# STM32F070RBT6 register map
File version: 1.0
Registers are 32-bit, access not given, reset 0x0 unless marked. A register's access mark holds for its fields unless they carry their own. Offsets are from the block's base; [hi:lo] are bit positions; {n}, {i} and the like mark numbered series.

## WWDG
Base 0x40002C00
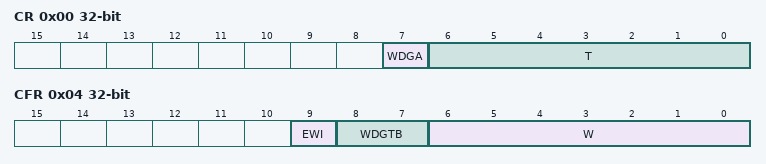
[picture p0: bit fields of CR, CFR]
0x00 CR
  [7] WDGA, [6:0] T
0x04 CFR
  [9] EWI, [8:7] WDGTB, [6:0] W
0x08 SR
  [0] EWIF

## IWDG
Base 0x40003000
0x00 KR
  [15:0] KEY
0x04 PR
  [2:0] PR
0x08 RLR
  [11:0] RL
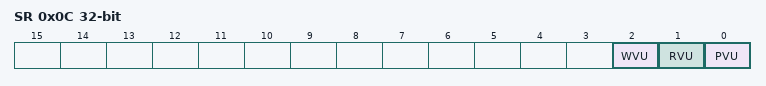
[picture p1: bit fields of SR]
0x0C SR
  [2] WVU, [1] RVU, [0] PVU
0x10 WINR
  [11:0] WIN

## SPI2
Base 0x40003800
Same registers: SPI1 0x40013000
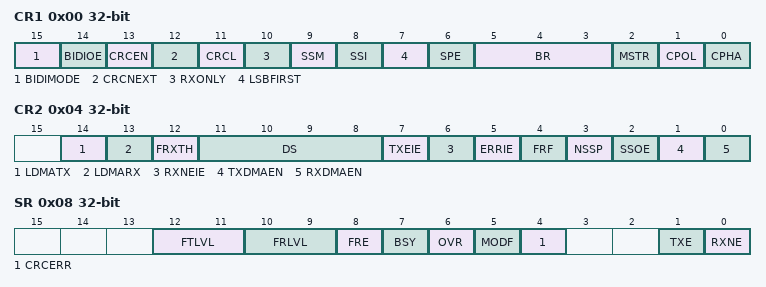
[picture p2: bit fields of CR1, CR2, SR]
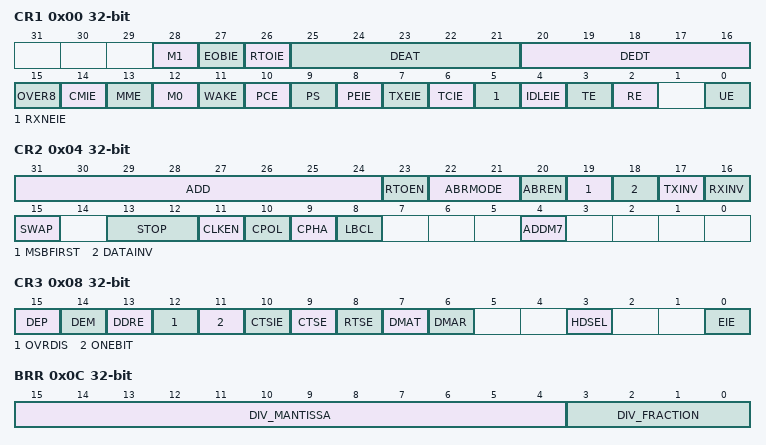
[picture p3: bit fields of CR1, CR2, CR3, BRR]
0x00 CR1
  [15] BIDIMODE, [14] BIDIOE, [13] CRCEN, [12] CRCNEXT, [11] CRCL, [10] RXONLY, [9] SSM, [8] SSI, [7] LSBFIRST, [6] SPE, [5:3] BR, [2] MSTR, [1] CPOL, [0] CPHA
0x04 CR2
  [14] LDMATX, [13] LDMARX, [12] FRXTH, [11:8] DS, [7] TXEIE, [6] RXNEIE, [5] ERRIE, [4] FRF, [3] NSSP, [2] SSOE, [1] TXDMAEN, [0] RXDMAEN
0x08 SR
  [12:11] FTLVL, [10:9] FRLVL, [8] FRE, [7] BSY, [6] OVR, [5] MODF, [4] CRCERR, [1] TXE, [0] RXNE
0x0C DR
0x10 CRCPR
  [31:0] CRCPOLY
0x14 RXCRCR
  [31:0] RXCRC
0x18 TXCRCR
  [31:0] TXCRC
0x1C I2SCFGR
  [11] I2SMOD

## USART2
Base 0x40004400
Same registers: USART3 0x40004800, USART4 0x40004C00, USART1 0x40013800
0x00 CR1
  [28] M1, [27] EOBIE, [26] RTOIE, [25:21] DEAT, [20:16] DEDT, [15] OVER8, [14] CMIE, [13] MME, [12] M0, [11] WAKE, [10] PCE, [9] PS, [8] PEIE, [7] TXEIE, [6] TCIE, [5] RXNEIE, [4] IDLEIE, [3] TE, [2] RE, [0] UE
0x04 CR2
  [31:24] ADD, [23] RTOEN, [22:21] ABRMODE, [20] ABREN, [19] MSBFIRST, [18] DATAINV, [17] TXINV, [16] RXINV, [15] SWAP, [13:12] STOP, [11] CLKEN, [10] CPOL, [9] CPHA, [8] LBCL, [4] ADDM7
0x08 CR3
  [15] DEP, [14] DEM, [13] DDRE, [12] OVRDIS, [11] ONEBIT, [10] CTSIE, [9] CTSE, [8] RTSE, [7] DMAT, [6] DMAR, [3] HDSEL, [0] EIE
0x0C BRR
  [15:4] DIV_MANTISSA, [3:0] DIV_FRACTION
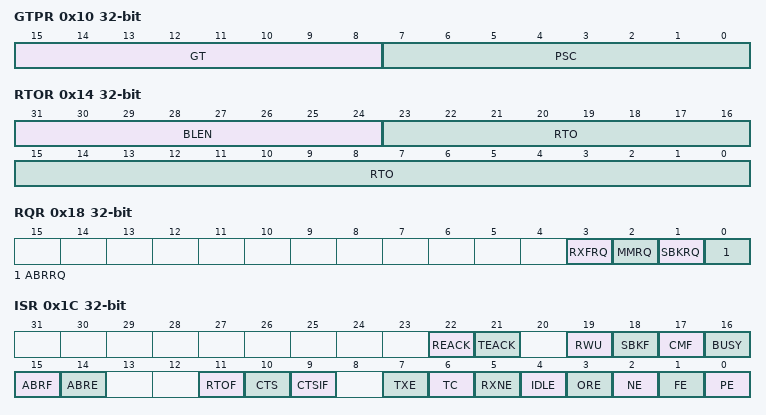
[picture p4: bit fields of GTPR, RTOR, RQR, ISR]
0x10 GTPR
  [15:8] GT, [7:0] PSC
0x14 RTOR
  [31:24] BLEN, [23:0] RTO
0x18 RQR
  [3] RXFRQ, [2] MMRQ, [1] SBKRQ, [0] ABRRQ
0x1C ISR
  [22] REACK, [21] TEACK, [19] RWU, [18] SBKF, [17] CMF, [16] BUSY, [15] ABRF, [14] ABRE, [11] RTOF, [10] CTS, [9] CTSIF, [7] TXE, [6] TC, [5] RXNE, [4] IDLE, [3] ORE, [2] NE, [1] FE, [0] PE
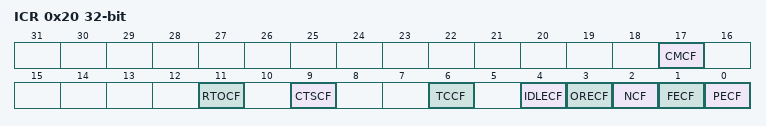
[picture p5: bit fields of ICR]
0x20 ICR
  [17] CMCF, [11] RTOCF, [9] CTSCF, [6] TCCF, [4] IDLECF, [3] ORECF, [2] NCF, [1] FECF, [0] PECF
0x24 RDR 16-bit
0x28 TDR 16-bit

## I2C1
Base 0x40005400
Same registers: I2C2 0x40005800
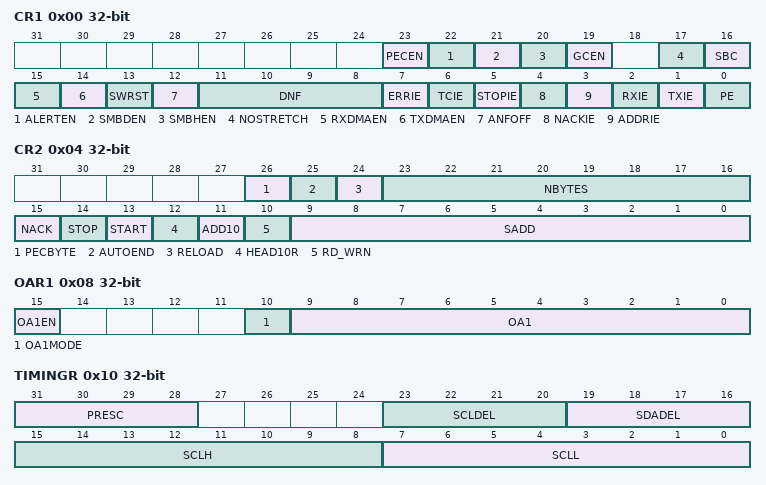
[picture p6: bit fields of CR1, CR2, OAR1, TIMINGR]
0x00 CR1
  [23] PECEN, [22] ALERTEN, [21] SMBDEN, [20] SMBHEN, [19] GCEN, [17] NOSTRETCH, [16] SBC, [15] RXDMAEN, [14] TXDMAEN, [13] SWRST, [12] ANFOFF, [11:8] DNF, [7] ERRIE, [6] TCIE, [5] STOPIE, [4] NACKIE, [3] ADDRIE, [2] RXIE, [1] TXIE, [0] PE
0x04 CR2
  [26] PECBYTE, [25] AUTOEND, [24] RELOAD, [23:16] NBYTES, [15] NACK, [14] STOP, [13] START, [12] HEAD10R, [11] ADD10, [10] RD_WRN, [9:0] SADD
0x08 OAR1
  [15] OA1EN, [10] OA1MODE, [9:0] OA1
0x0C OAR2
  [15] OA2EN, [10] OA2MASK04, [10:9] OA2MASK06, [10:8] OA2MSK, [7:1] OA2
0x10 TIMINGR
  [31:28] PRESC, [23:20] SCLDEL, [19:16] SDADEL, [15:8] SCLH, [7:0] SCLL
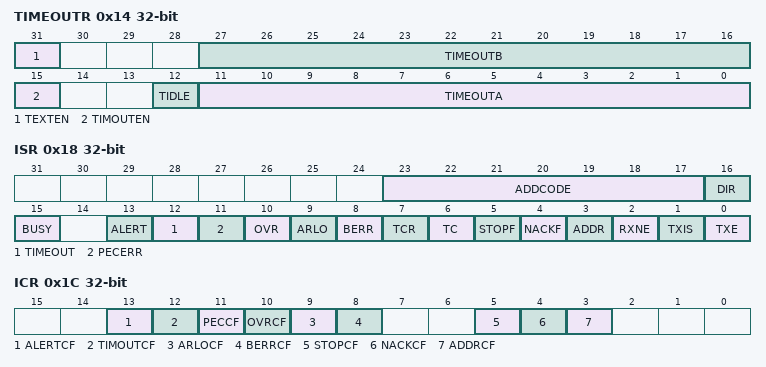
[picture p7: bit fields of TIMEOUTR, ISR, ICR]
0x14 TIMEOUTR
  [31] TEXTEN, [27:16] TIMEOUTB, [15] TIMOUTEN, [12] TIDLE, [11:0] TIMEOUTA
0x18 ISR
  [23:17] ADDCODE, [16] DIR, [15] BUSY, [13] ALERT, [12] TIMEOUT, [11] PECERR, [10] OVR, [9] ARLO, [8] BERR, [7] TCR, [6] TC, [5] STOPF, [4] NACKF, [3] ADDR, [2] RXNE, [1] TXIS, [0] TXE
0x1C ICR
  [13] ALERTCF, [12] TIMOUTCF, [11] PECCF, [10] OVRCF, [9] ARLOCF, [8] BERRCF, [5] STOPCF, [4] NACKCF, [3] ADDRCF
0x20 PECR
  [7:0] PEC
0x24 RXDR
  [7:0] RXDATA
0x28 TXDR
  [7:0] TXDATA

## USB
Base 0x40005C00
{0x0+4i} EP{i}R 16-bit (i=0..7)
0x40 CNTR 16-bit
0x44 ISTR 16-bit
0x48 FNR 16-bit
0x4C DADDR 16-bit
0x50 BTABLE 16-bit
0x54 LPMCSR 16-bit
0x58 BCDR 16-bit

## PWR
Base 0x40007000
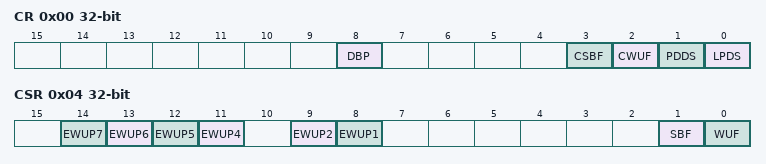
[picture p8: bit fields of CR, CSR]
0x00 CR
  [8] DBP, [3] CSBF, [2] CWUF, [1] PDDS, [0] LPDS
0x04 CSR
  [n+7] EWUP{n} (n=4..7), [9] EWUP2, [8] EWUP1, [1] SBF, [0] WUF

## SYSCFG
Base 0x40010000
0x00 CFGR1
  [26] USART3_DMA_RMP, [20] I2C_FMP_I2C1, [n+10] I2C_FMP_PB{n} (n=6..9), [12] TIM17_DMA_RMP, [11] TIM16_DMA_RMP, [10] USART1RX_DMA_RMP, [9] USART1TX_DMA_RMP, [26:8] DMA_RMP, [1:0] MEM_MODE
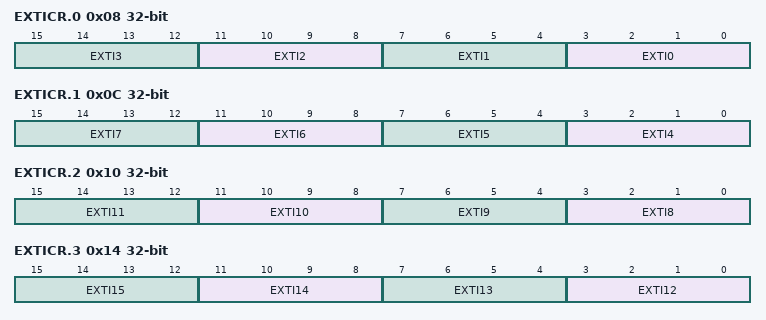
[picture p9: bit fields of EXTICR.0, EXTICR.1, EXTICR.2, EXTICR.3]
0x08 EXTICR.0
  [4n+3:4n] EXTI{n} (n=0..3)
0x0C EXTICR.1
  [4n-13:4n-16] EXTI{n} (n=4..7)
0x10 EXTICR.2
  [4n-29:4n-32] EXTI{n} (n=8..11)
0x14 EXTICR.3
  [4n-45:4n-48] EXTI{n} (n=12..15)
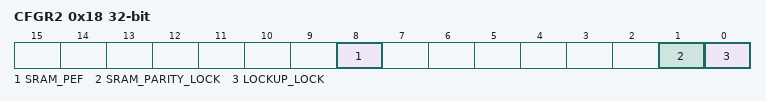
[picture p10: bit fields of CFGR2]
0x18 CFGR2
  [8] SRAM_PEF, [1] SRAM_PARITY_LOCK, [0] LOCKUP_LOCK
